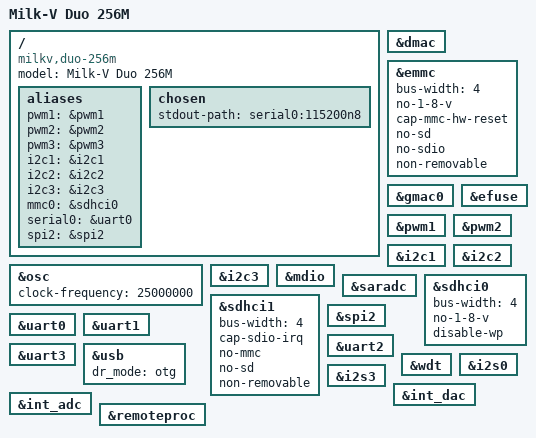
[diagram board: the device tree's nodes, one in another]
// SPDX-License-Identifier: (GPL-2.0 OR MIT)

/dts-v1/;

#include "sg2002.dtsi"

/ {
	model = "Milk-V Duo 256M";
	compatible = "milkv,duo-256m", "sophgo,sg2002";

	aliases {
		pwm1 = &pwm1;
		pwm2 = &pwm2;
		pwm3 = &pwm3;
		i2c1 = &i2c1;
		i2c2 = &i2c2;
		i2c3 = &i2c3;
		mmc0 = &sdhci0;
		serial0 = &uart0;
		spi2 = &spi2;
	};

	chosen {
		stdout-path = "serial0:115200n8";
	};
};

&osc {
	clock-frequency = <25000000>;
};

&dmac {
	status = "okay";
};

&emmc {
	bus-width = <4>;
	no-1-8-v;
	cap-mmc-hw-reset;
	no-sd;
	no-sdio;
	non-removable;
	status = "okay";
};

&gmac0 {
	status = "okay";
};

&efuse {
	status = "okay";
};

&pwm1 {
	status = "okay";
};

&pwm2 {
	status = "okay";
};

&i2c1 {
	status = "okay";
};

&i2c2 {
	status = "okay";
};

&i2c3 {
	status = "okay";
};

&mdio {
	status = "okay";
};

&saradc {
	status = "okay";
};

&sdhci0 {
	bus-width = <4>;
	no-1-8-v;
	disable-wp;
	status = "okay";
};

&sdhci1 {
	bus-width = <4>;
	cap-sdio-irq;
	no-mmc;
	no-sd;
	non-removable;
	status = "okay";
};

&spi2 {
	status = "okay";
};

&uart0 {
	status = "okay";
};

&uart1 {
	status = "okay";
};

&uart2 {
	status = "okay";
};

&uart3 {
	status = "okay";
};

&usb {
	dr_mode = "otg";
	status = "okay";
};

&wdt {
	status = "okay";
};

&i2s0 {
	status = "okay";
	#sound-dai-cells = <0>;
};

&i2s3 {
	status = "okay";
	#sound-dai-cells = <0>;
};

&int_dac {
	status = "okay";
};

&int_adc {
	status = "okay";
	#sound-dai-cells = <0>;
	/delete-property/ mute-gpio-l;
	/delete-property/ mute-gpio-r;
};

&remoteproc {
	status = "okay";
};
